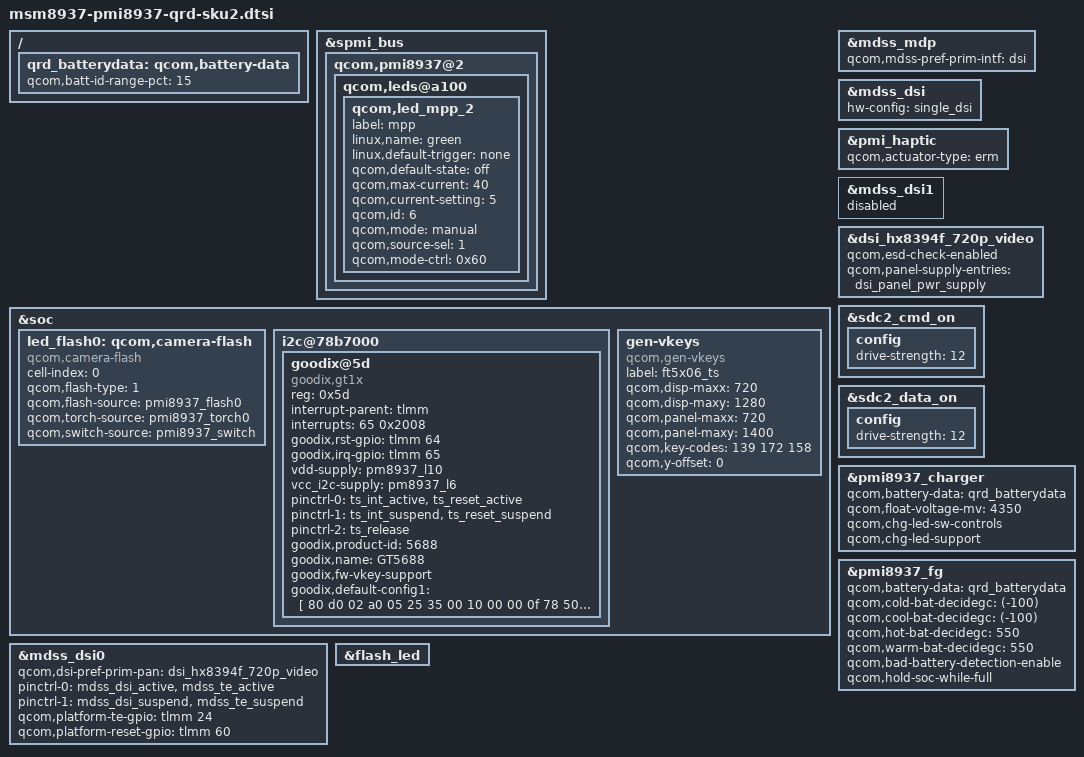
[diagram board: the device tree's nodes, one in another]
/*
 * Copyright (c) 2015-2016, The Linux Foundation. All rights reserved.
 *
 * This program is free software; you can redistribute it and/or modify
 * it under the terms of the GNU General Public License version 2 and
 * only version 2 as published by the Free Software Foundation.
 *
 * This program is distributed in the hope that it will be useful,
 * but WITHOUT ANY WARRANTY; without even the implied warranty of
 * MERCHANTABILITY or FITNESS FOR A PARTICULAR PURPOSE.  See the
 * GNU General Public License for more details.
 */

#include "msm-pmi8937.dtsi"
#include "msm8937-qrd.dtsi"
#include "msm8937-mdss-panels.dtsi"

&spmi_bus {
	qcom,pmi8937@2 {
		qcom,leds@a100 {
			status = "okay";
			qcom,led_mpp_2 {
				label = "mpp";
				linux,name = "green";
				linux,default-trigger = "none";
				qcom,default-state = "off";
				qcom,max-current = <40>;
				qcom,current-setting = <5>;
				qcom,id = <6>;
				qcom,mode = "manual";
				qcom,source-sel = <1>;
				qcom,mode-ctrl = <0x60>;
			};
		};
	};
};

&soc {
	led_flash0: qcom,camera-flash {
		cell-index = <0>;
		compatible = "qcom,camera-flash";
		qcom,flash-type = <1>;
		qcom,flash-source = <&pmi8937_flash0>;
		qcom,torch-source = <&pmi8937_torch0>;
		qcom,switch-source = <&pmi8937_switch>;
	};

	i2c@78b7000 {
		status = "ok";
		goodix@5d {
			compatible = "goodix,gt1x";
			reg = <0x5d>;
			interrupt-parent = <&tlmm>;
			interrupts = <65 0x2008>;
			goodix,rst-gpio = <&tlmm 64 0x0>;
			goodix,irq-gpio = <&tlmm 65 0x2002>;
			vdd-supply = <&pm8937_l10>;
			vcc_i2c-supply = <&pm8937_l6>;
			pinctrl-names = "pmx_ts_active", "pmx_ts_suspend", "pmx_ts_release";
			pinctrl-0 = <&ts_int_active &ts_reset_active>;
			pinctrl-1 = <&ts_int_suspend &ts_reset_suspend>;
			pinctrl-2 = <&ts_release>;
			goodix,product-id = "5688";
			goodix,name = "GT5688";
			goodix,fw-vkey-support;
			/* SensorID 1 config (CFG_GROUP1), 239 bytes, 720x1440 */
			goodix,default-config1 = [
				80 d0 02 a0 05 25 35 00 10 00 00 0f 78 50 53 11
				01 01 00 00 14 17 19 1d 0a 04 70 00 0a 05 00 58
				53 00 14 00 00 84 00 00 3c 00 00 64 1e 1e 8b 0b
				0d 28 2a 0c 08 60 3b 62 ba 02 24 00 00 50 8c c0
				14 02 02 00 00 a2 5a 94 64 89 6e 80 78 78 82 72
				00 00 00 00 00 00 00 f0 50 3c aa aa 07 00 00 00
				00 14 14 03 04 00 21 64 0a 00 00 00 00 00 00 00
				00 00 00 00 00 00 00 00 00 00 00 00 00 00 00 00
				df 07 32 20 50 3c 3c 00 00 00 00 00 0d 06 0c 05
				0b 04 0a 03 09 02 08 01 07 ff 0b 0c 0d 0e 0f 10
				11 12 13 14 15 0a 09 08 07 06 05 04 03 02 01 00
				ff ff ff ff 00 00 00 00 00 00 00 00 00 00 00 00
				00 50 3c 00 05 1e 00 03 1c 1e 19 14 02 00 03 0a
				05 32 64 00 00 00 00 00 01 ff ff 84 22 03 df 07
				3b f0 0a 1e 00 78 50 3c 20 00 00 05 ff ba 01
			];
		};

	};

	gen-vkeys {
		compatible = "qcom,gen-vkeys";
		label = "ft5x06_ts";
		qcom,disp-maxx = <720>;
		qcom,disp-maxy = <1280>;
		qcom,panel-maxx = <720>;
		qcom,panel-maxy = <1400>;
		qcom,key-codes = <139 172 158>;
		qcom,y-offset = <0>;
	};
};

&mdss_mdp {
	qcom,mdss-pref-prim-intf = "dsi";
};

&mdss_dsi {
	hw-config = "single_dsi";
};

&mdss_dsi0 {
	qcom,dsi-pref-prim-pan = <&dsi_hx8394f_720p_video>;
	pinctrl-names = "mdss_default", "mdss_sleep";
	pinctrl-0 = <&mdss_dsi_active &mdss_te_active>;
	pinctrl-1 = <&mdss_dsi_suspend &mdss_te_suspend>;

	qcom,platform-te-gpio = <&tlmm 24 0>;
	qcom,platform-reset-gpio = <&tlmm 60 0>;
};

&pmi_haptic {
	status = "okay";
	qcom,actuator-type = "erm";
	/delete-property/ qcom,lra-auto-res-mode;
	/delete-property/ qcom,lra-high-z;
	/delete-property/ qcom,lra-res-cal-period;
	/delete-property/ qcom,correct-lra-drive-freq;
	/delete-property/ qcom,misc-trim-error-rc19p2-clk-reg-present;
};

&mdss_dsi1 {
	status = "disabled";
};

&dsi_hx8394f_720p_video {
	qcom,esd-check-enabled;
	qcom,panel-supply-entries = <&dsi_panel_pwr_supply>;
};

&sdc2_cmd_on {
	config {
		drive-strength = <12>;
	};
};

&sdc2_data_on {
	config {
		drive-strength = <12>;
	};
};

/ {
	qrd_batterydata: qcom,battery-data {
		qcom,batt-id-range-pct = <15>;
		#include "batterydata-qrd-sku2-4v35-2590mah.dtsi"
	};
};

&pmi8937_charger {
	qcom,battery-data = <&qrd_batterydata>;
	qcom,float-voltage-mv = <4350>;
	qcom,chg-led-sw-controls;
	qcom,chg-led-support;
	status = "okay";
};

&pmi8937_fg {
	qcom,battery-data = <&qrd_batterydata>;
	qcom,cold-bat-decidegc = <(-100)>;
	qcom,cool-bat-decidegc = <(-100)>;
	qcom,hot-bat-decidegc = <550>;
	qcom,warm-bat-decidegc = <550>;
	qcom,bad-battery-detection-enable;
	qcom,hold-soc-while-full;
};

&flash_led {
	/delete-node/ qcom,flash_1;
	/delete-node/ qcom,torch_1;
};
